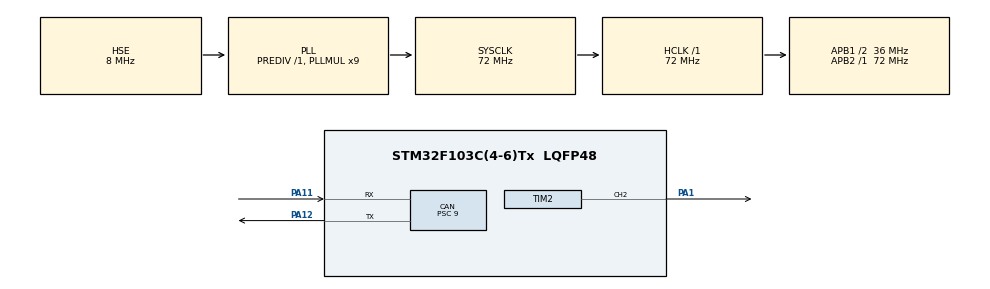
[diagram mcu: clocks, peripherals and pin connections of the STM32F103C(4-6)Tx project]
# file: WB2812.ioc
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CAN.BS1=CAN_BS1_6TQ
CAN.CalculateBaudRate=500000
CAN.CalculateTimeBit=2000
CAN.CalculateTimeQuantum=250.0
CAN.Mode=CAN_MODE_NORMAL
CAN.Prescaler=9
CAN.SJW=CAN_SJW_3TQ
Dma.Request0=TIM2_CH2/CH4
Dma.TIM2_CH2/CH4.0.Direction=DMA_MEMORY_TO_PERIPH
Dma.TIM2_CH2/CH4.0.Instance=DMA1_Channel7
Dma.TIM2_CH2/CH4.0.MemDataAlignment=DMA_MDATAALIGN_WORD
Dma.TIM2_CH2/CH4.0.MemInc=DMA_MINC_ENABLE
Dma.TIM2_CH2/CH4.0.Mode=DMA_CIRCULAR
Dma.TIM2_CH2/CH4.0.PeriphDataAlignment=DMA_PDATAALIGN_WORD
Dma.TIM2_CH2/CH4.0.PeriphInc=DMA_PINC_DISABLE
Dma.TIM2_CH2/CH4.0.Priority=DMA_PRIORITY_HIGH
Mcu.Family=STM32F1
Mcu.Name=STM32F103C(4-6)Tx
Mcu.Package=LQFP48
NVIC.CAN1_RX1_IRQn=true\:1\:0\:true\:false\:true\:true\:true\:true
NVIC.DMA1_Channel7_IRQn=true\:2\:0\:true\:false\:true\:false\:true\:true
NVIC.PriorityGroup=NVIC_PRIORITYGROUP_4
NVIC.USB_LP_CAN1_RX0_IRQn=true\:1\:0\:true\:false\:true\:true\:true\:true
PA1.Signal=S_TIM2_CH2
PA11.Mode=CAN_Activate
PA11.Signal=CAN_RX
PA12.Mode=CAN_Activate
PA12.Signal=CAN_TX
PA13.Mode=Serial_Wire
PA13.Signal=SYS_JTMS-SWDIO
PA14.Mode=Serial_Wire
PA14.Signal=SYS_JTCK-SWCLK
PD0-OSC_IN.Mode=HSE-External-Oscillator
PD0-OSC_IN.Signal=RCC_OSC_IN
PD1-OSC_OUT.Mode=HSE-External-Oscillator
PD1-OSC_OUT.Signal=RCC_OSC_OUT
ProjectManager.HeapSize=0x200
ProjectManager.StackSize=0x400
ProjectManager.TargetToolchain=STM32CubeIDE
RCC.AHBFreq_Value=72000000
RCC.APB1CLKDivider=RCC_HCLK_DIV2
RCC.APB1Freq_Value=36000000
RCC.APB1TimFreq_Value=72000000
RCC.APB2Freq_Value=72000000
RCC.APB2TimFreq_Value=72000000
RCC.HCLKFreq_Value=72000000
RCC.PLLMUL=RCC_PLL_MUL9
RCC.PLLSourceVirtual=RCC_PLLSOURCE_HSE
RCC.SYSCLKFreq_VALUE=72000000
RCC.SYSCLKSource=RCC_SYSCLKSOURCE_PLLCLK
RCC.USBFreq_Value=72000000
SH.S_TIM2_CH2.0=TIM2_CH2,PWM Generation2 CH2
TIM2.AutoReloadPreload=TIM_AUTORELOAD_PRELOAD_ENABLE
TIM2.Channel-PWM\ Generation2\ CH2=TIM_CHANNEL_2
TIM2.Period=89
VP_TIM2_VS_ClockSourceINT.Mode=Internal
board=custom

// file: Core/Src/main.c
/* USER CODE BEGIN Header */
/**
  ******************************************************************************
  * @file           : main.c
  * @brief          : Main program body
  ******************************************************************************
  * @attention
  *
  * Copyright (c) 2023 STMicroelectronics.
  * All rights reserved.
  *
  * This software is licensed under terms that can be found in the LICENSE file
  * in the root directory of this software component.
  * If no LICENSE file comes with this software, it is provided AS-IS.
  *
  ******************************************************************************
  */
/* USER CODE END Header */
#include "main.h"
#include "can.h"
#include "dma.h"
#include "tim.h"
#include "gpio.h"

/* USER CODE BEGIN Includes */
#include "ARGB.h"
/* USER CODE END Includes */

/* USER CODE BEGIN PTD */
extern uint8_t RxData[8];
/* USER CODE END PTD */

void SystemClock_Config(void);

int main(void)
{

  /* MCU Configuration--------------------------------------------------------*/

  /* Reset of all peripherals, Initializes the Flash interface and the Systick. */
  HAL_Init();

  /* Configure the system clock */
  SystemClock_Config();

  /* Initialize all configured peripherals */
  MX_GPIO_Init();
  MX_DMA_Init();
  MX_TIM2_Init();
  MX_CAN_Init();

  /* USER CODE BEGIN 2 */

  CAN_Start();
  ARGB_SetBrightness(255);
  ARGB_Init();  // Initialization
  ARGB_Clear();

  /* USER CODE END 2 */

  /* Infinite loop */
  while (1)
  {

    /* USER CODE BEGIN 3 */

	  switch ( RxData[4]){
	  	  case 129:
	  		// Fill all the strip with Red
	  	    ARGB_FillRGB(255, 0, 0);
	  	    ARGB_Show();
	  		break;
	  	  case 130:
	  		 // Fill all the strip with Green
	  	    ARGB_FillRGB(0, 255, 0);
	  	    ARGB_Show();
	  		break;
	  	  case 131:
	  		// Fill all the strip with Blue
	  	    ARGB_FillRGB(0, 0, 255);
	  	    ARGB_Show();
	  		break;
	  	  case 132:
	  		// Fill all the strip with Yellow
	  	    ARGB_FillRGB(255, 255, 0);
	  	    ARGB_Show();
	  		break;
	  }

  }
  /* USER CODE END 3 */
}

void SystemClock_Config(void)
{
  RCC_OscInitTypeDef RCC_OscInitStruct = {0};
  RCC_ClkInitTypeDef RCC_ClkInitStruct = {0};

  /** Initializes the RCC Oscillators according to the specified parameters
  * in the RCC_OscInitTypeDef structure.
  */
  RCC_OscInitStruct.OscillatorType = RCC_OSCILLATORTYPE_HSE;
  RCC_OscInitStruct.HSEState = RCC_HSE_ON;
  RCC_OscInitStruct.HSEPredivValue = RCC_HSE_PREDIV_DIV1;
  RCC_OscInitStruct.HSIState = RCC_HSI_ON;
  RCC_OscInitStruct.PLL.PLLState = RCC_PLL_ON;
  RCC_OscInitStruct.PLL.PLLSource = RCC_PLLSOURCE_HSE;
  RCC_OscInitStruct.PLL.PLLMUL = RCC_PLL_MUL9;
  if (HAL_RCC_OscConfig(&RCC_OscInitStruct) != HAL_OK)
  {
    Error_Handler();
  }

  /** Initializes the CPU, AHB and APB buses clocks
  */
  RCC_ClkInitStruct.ClockType = RCC_CLOCKTYPE_HCLK|RCC_CLOCKTYPE_SYSCLK
                              |RCC_CLOCKTYPE_PCLK1|RCC_CLOCKTYPE_PCLK2;
  RCC_ClkInitStruct.SYSCLKSource = RCC_SYSCLKSOURCE_PLLCLK;
  RCC_ClkInitStruct.AHBCLKDivider = RCC_SYSCLK_DIV1;
  RCC_ClkInitStruct.APB1CLKDivider = RCC_HCLK_DIV2;
  RCC_ClkInitStruct.APB2CLKDivider = RCC_HCLK_DIV1;

  if (HAL_RCC_ClockConfig(&RCC_ClkInitStruct, FLASH_LATENCY_2) != HAL_OK)
  {
    Error_Handler();
  }
}

void Error_Handler(void)
{
  __disable_irq();
  while (1)
  {
  }
}
